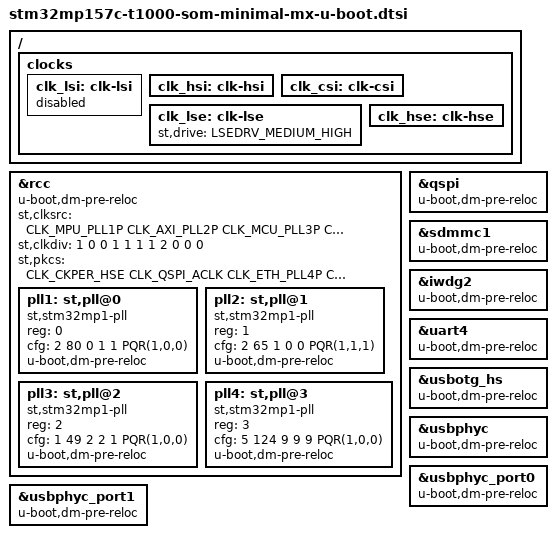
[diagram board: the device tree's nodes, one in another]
/* SPDX-License-Identifier: GPL-2.0+ OR BSD-3-Clause*/
/*
 * Copyright (C) 2022, STMicroelectronics - All Rights Reserved
 * Author: STM32CubeMX code generation for STMicroelectronics.
 */

/* For more information on Device Tree configuration, please refer to
 * https://wiki.st.com/stm32mpu/wiki/Category:Device_tree_configuration
 */

#include <dt-bindings/clock/stm32mp1-clksrc.h>
#include "stm32mp15-mx.dtsi"

#include "stm32mp15-u-boot.dtsi"
#include "stm32mp15-ddr.dtsi"

/* USER CODE BEGIN includes */
/* USER CODE END includes */

/ {

	/* USER CODE BEGIN root */
	/* USER CODE END root */

	clocks {
		/* USER CODE BEGIN clocks */
		/* USER CODE END clocks */

#ifndef CONFIG_TFABOOT
		clk_lsi: clk-lsi {
			status = "disabled";

			/* USER CODE BEGIN clk_lsi */
			/* USER CODE END clk_lsi */
		};
		clk_hsi: clk-hsi {

			/* USER CODE BEGIN clk_hsi */
			/* USER CODE END clk_hsi */
		};
		clk_csi: clk-csi {

			/* USER CODE BEGIN clk_csi */
			/* USER CODE END clk_csi */
		};
		clk_lse: clk-lse {
			st,drive = < LSEDRV_MEDIUM_HIGH >;

			/* USER CODE BEGIN clk_lse */
			/* USER CODE END clk_lse */
		};
		clk_hse: clk-hse {

			/* USER CODE BEGIN clk_hse */
			/* USER CODE END clk_hse */
		};
#endif	/*CONFIG_TFABOOT*/
	};

}; /*root*/

#ifndef CONFIG_TFABOOT

&rcc{
	u-boot,dm-pre-reloc;
	st,clksrc = <
		CLK_MPU_PLL1P
		CLK_AXI_PLL2P
		CLK_MCU_PLL3P
		CLK_PLL12_HSE
		CLK_PLL3_HSE
		CLK_PLL4_HSE
		CLK_RTC_LSE
		CLK_MCO1_DISABLED
		CLK_MCO2_DISABLED
	>;
	st,clkdiv = <
		1 		/*MPU*/
		0 		/*AXI*/
		0 		/*MCU*/
		1 		/*APB1*/
		1 		/*APB2*/
		1 		/*APB3*/
		1 		/*APB4*/
		2 		/*APB5*/
		0 		/*RTC*/
		0 		/*MCO1*/
		0 		/*MCO2*/
	>;
	st,pkcs = <
		CLK_CKPER_HSE
		CLK_QSPI_ACLK
		CLK_ETH_PLL4P
		CLK_SDMMC12_PLL4P
		CLK_STGEN_HSE
		CLK_USBPHY_HSE
		CLK_SPI2S1_DISABLED
		CLK_SPI2S23_DISABLED
		CLK_SPI45_DISABLED
		CLK_SPI6_DISABLED
		CLK_I2C46_DISABLED
		CLK_SDMMC3_DISABLED
		CLK_USBO_USBPHY
		CLK_ADC_CKPER
		CLK_CEC_DISABLED
		CLK_I2C12_HSI
		CLK_I2C35_DISABLED
		CLK_UART1_DISABLED
		CLK_UART24_PCLK1
		CLK_UART35_DISABLED
		CLK_UART6_DISABLED
		CLK_UART78_DISABLED
		CLK_SPDIF_DISABLED
		CLK_SAI1_DISABLED
		CLK_SAI2_DISABLED
		CLK_SAI3_DISABLED
		CLK_SAI4_DISABLED
		CLK_RNG1_CSI
		CLK_RNG2_CSI
		CLK_LPTIM1_DISABLED
		CLK_LPTIM23_DISABLED
		CLK_LPTIM45_DISABLED
	>;
	pll1:st,pll@0 {
		compatible = "st,stm32mp1-pll";
		reg = <0>;
		cfg = < 2 80 0 1 1 PQR(1,0,0) >;
		u-boot,dm-pre-reloc;
	};
	pll2:st,pll@1 {
		compatible = "st,stm32mp1-pll";
		reg = <1>;
		cfg = < 2 65 1 0 0 PQR(1,1,1) >;
		u-boot,dm-pre-reloc;
	};
	pll3:st,pll@2 {
		compatible = "st,stm32mp1-pll";
		reg = <2>;
		cfg = < 1 49 2 2 1 PQR(1,0,0) >;
		u-boot,dm-pre-reloc;
	};
	pll4:st,pll@3 {
		compatible = "st,stm32mp1-pll";
		reg = <3>;
		cfg = < 5 124 9 9 9 PQR(1,0,0) >;
		u-boot,dm-pre-reloc;
	};

	/* USER CODE BEGIN rcc */
	/* USER CODE END rcc */
};

&qspi{
	u-boot,dm-pre-reloc;

	/* USER CODE BEGIN qspi */
	/* USER CODE END qspi */
};

&sdmmc1{
	u-boot,dm-pre-reloc;

	/* USER CODE BEGIN sdmmc1 */
	/* USER CODE END sdmmc1 */
};

#endif	/*CONFIG_TFABOOT*/

&iwdg2{
	u-boot,dm-pre-reloc;

	/* USER CODE BEGIN iwdg2 */
	/* USER CODE END iwdg2 */
};

&uart4{
	u-boot,dm-pre-reloc;

	/* USER CODE BEGIN uart4 */
	/* USER CODE END uart4 */
};

&usbotg_hs{
	u-boot,dm-pre-reloc;

	/* USER CODE BEGIN usbotg_hs */
	/* USER CODE END usbotg_hs */
};

&usbphyc{
	u-boot,dm-pre-reloc;

	/* USER CODE BEGIN usbphyc */
	/* USER CODE END usbphyc */
};

&usbphyc_port0{
	u-boot,dm-pre-reloc;

	/* USER CODE BEGIN usbphyc_port0 */
	/* USER CODE END usbphyc_port0 */
};

&usbphyc_port1{
	u-boot,dm-pre-reloc;

	/* USER CODE BEGIN usbphyc_port1 */
	/* USER CODE END usbphyc_port1 */
};

/* USER CODE BEGIN addons */
/* USER CODE END addons */

